# cpsw_ale register map
Vendor: Texas Instruments
Peripheral module from a debugger description file (folder am335x).
Registers are 32-bit, read-write, no defined reset value unless marked. A register's access mark holds for its fields unless they carry their own. Offsets are as the file gives them; lines under a group give offsets from that group; [hi:lo] are bit positions; {n}, {i} and the like mark numbered series; 'fields as' and 'values as' point back to an identical list; <NAME> marks a mode.

## cpsw_ale
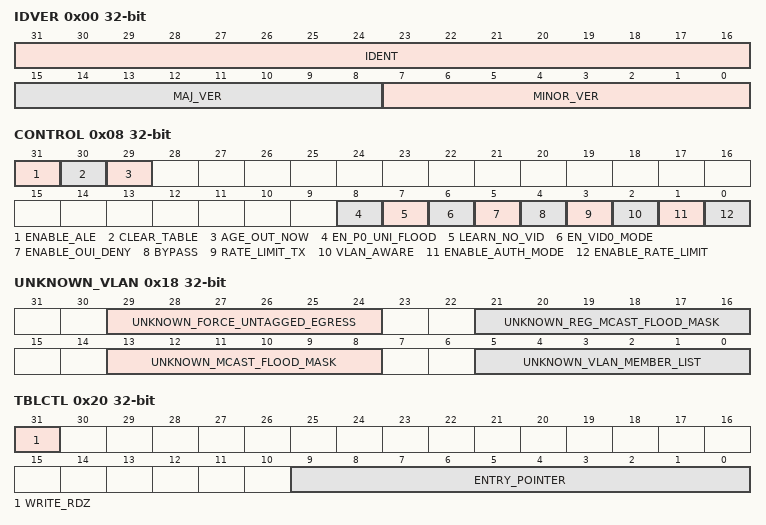
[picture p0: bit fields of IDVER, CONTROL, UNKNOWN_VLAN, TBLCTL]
0x00 IDVER ro — ADDRESS LOOKUP ENGINE ID/VERSION REGISTER
  [31:16] IDENT — ALE Identification Value
  [15:8] MAJ_VER — ALE Major Version Value
  [7:0] MINOR_VER — ALE Minor Version Value
0x08 CONTROL — ADDRESS LOOKUP ENGINE CONTROL REGISTER
  [31] ENABLE_ALE — Enable ALE - 0 - Drop all packets 1 - Enable ALE packet processing
  [30] CLEAR_TABLE — Clear ALE address table - Setting this bit causes the ALE hardware to write all table bit values to zero. Software must perform a clear table operation as part of the ALE setup/configuration process. Setting this bit causes all ALE accesses to be held up for 64 clocks while the clear is performed. Access to all ALE registers will be blocked (wait states) until the 64 clocks have completed. This bit cannot be read as one because the read is blocked until the clear table is completed at which time this bit is cleared to zero.
  [29] AGE_OUT_NOW — Age Out Address Table Now - Setting this bit causes the ALE hardware to remove (free up) any ageable table entry that does not have a set touch bit. This bit is cleared when the age out process has completed. This bit may be read. The age out process takes 4096 clocks best case (no ale packet processing during ageout) and 66550 clocks absolute worst case.
  [8] EN_P0_UNI_FLOOD — Enable Port 0 (Host Port) unicast flood 0 - do not flood unknown unicast packets to host port (p0) 1 - flood unknown unicast packets to host port (p0)
  [7] LEARN_NO_VID — Learn No VID - 0 - VID is learned with the source address 1 - VID is not learned with the source address (source address is not tied to VID).
  [6] EN_VID0_MODE — Enable VLAN ID = 0 Mode 0 - Process the packet with VID = PORT_VLAN[11:0]. 1 - Process the packet with VID = 0.
  [5] ENABLE_OUI_DENY — Enable OUI Deny Mode - When set this bit indicates that a packet with a non OUI table entry matching source address will be dropped to the host unless the destination address matches a multicast table entry with the super bit set.
  [4] BYPASS — ALE Bypass - When set, all packets received on ports 0 and 1 are sent to the host (only to the host).
  [3] RATE_LIMIT_TX — Rate Limit Transmit mode - 0 - Broadcast and multicast rate limit counters are received port based 1 - Broadcast and multicast rate limit counters are transmit port based.
  [2] VLAN_AWARE — ALE VLAN Aware - Determines what is done if VLAN not found. 0 - Flood if VLAN not found 1 - Drop packet if VLAN not found
  [1] ENABLE_AUTH_MODE — Enable MAC Authorization Mode - Mac authorization mode requires that all table entries be made by the host software. There are no learned address in authorization mode and the packet will be dropped if the source address is not found (and the destination address is not a multicast address with the super table entry bit set). 0 - The ALE is not in MAC authorization mode 1 - The ALE is in MAC authorization mode
  [0] ENABLE_RATE_LIMIT — Enable Broadcast and Multicast Rate Limit 0 - Broadcast/Multicast rates not limited 1 - Broadcast/Multicast packet reception limited to the port control register rate limit fields.
0x10 PRESCALE — ADDRESS LOOKUP ENGINE PRESCALE REGISTER
  [19:0] PRESCALE — ALE Prescale Register - The input clock is divided by this value for use in the multicast/broadcast rate limiters. The minimum operating value is 0x10. The prescaler is off when the value is zero.
0x18 UNKNOWN_VLAN — ADDRESS LOOKUP ENGINE UNKNOWN VLAN REGISTER
  [29:24] UNKNOWN_FORCE_UNTAGGED_EGRESS — Unknown VLAN Force Untagged Egress.
  [21:16] UNKNOWN_REG_MCAST_FLOOD_MASK — Unknown VLAN Registered Multicast Flood Mask
  [13:8] UNKNOWN_MCAST_FLOOD_MASK — Unknown VLAN Multicast Flood Mask
  [5:0] UNKNOWN_VLAN_MEMBER_LIST
0x20 TBLCTL — ADDRESS LOOKUP ENGINE TABLE CONTROL
  [31] WRITE_RDZ — Write Bit - This bit is always read as zero. Writing a 1 to this bit causes the three table word register values to be written to the entry_pointer location in the address table. Writing a 0 to this bit causes the three table word register values to be loaded from the entry_pointer location in the address table so that they may be subsequently read. A read of any ALE address location will be stalled until the read or write has completed.
  [9:0] ENTRY_POINTER — Table Entry Pointer - The entry_pointer contains the table entry value that will be read/written with accesses to the table word registers.
0x34 TBLW2 — ADDRESS LOOKUP ENGINE TABLE WORD 2 REGISTER
  [7:0] ENTRY71_64 — Table entry bits 71:64
0x38 TBLW1 — ADDRESS LOOKUP ENGINE TABLE WORD 1 REGISTER
  [31:0] ENTRY63_32 — Table entry bits 63:32
0x3C TBLW0 — ADDRESS LOOKUP ENGINE TABLE WORD 0 REGISTER
  [31:0] ENTRY31_0 — Table entry bits 31:0
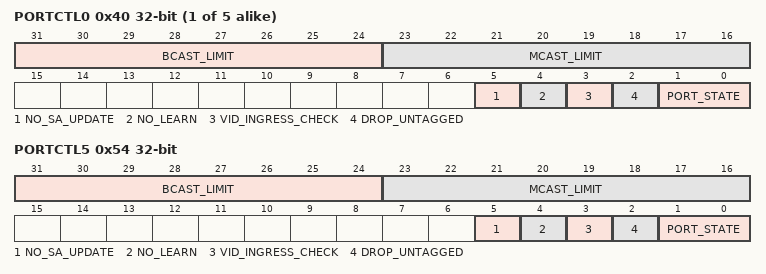
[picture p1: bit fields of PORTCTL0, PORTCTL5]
{0x40+4i} PORTCTL{i} (i=0..4) — ADDRESS LOOKUP ENGINE PORT {i} CONTROL REGISTER
  [31:24] BCAST_LIMIT — Broadcast Packet Rate Limit - Each prescale pulse loads this field into the port broadcast rate limit counter. The port counters are decremented with each packet received or transmitted depending on whether the mode is transmit or receive. If the counters decrement to zero, then further packets are rate limited until the next prescale pulse. Broadcast rate limiting is enabled by a non-zero value in this field
  [23:16] MCAST_LIMIT — Multicast Packet Rate Limit - Each prescale pulse loads this field into the port multicast rate limit counter. The port counters are decremented with each packet received or transmitted depending on whether the mode is transmit or receive. If the counters decrement to zero, then further packets are rate limited until the next prescale pulse. Multicast rate limiting is enabled by a non-zero value in this field.
  [5] NO_SA_UPDATE — No Souce Address Update - When set the port is disabled from updating the source port number in an ALE table entry.
  [4] NO_LEARN — No Learn Mode - When set the port is disabled from learning an address.
  [3] VID_INGRESS_CHECK — VLAN ID Ingress Check - If VLAN not found then drop the packet. Packets with an unknown (default) VLAN will be dropped.
  [2] DROP_UNTAGGED — Drop Untagged Packets - Drop non-VLAN tagged ingress packets.
  [1:0] PORT_STATE — Port State 0 - Disabled 1 - Blocked 2 - Learn 3 - Forward
0x54 PORTCTL5 — ADDRESS LOOKUP ENGINE PORT 5 CONTROL REGISTER
  [31:24] BCAST_LIMIT — Broadcast Packet Rate Limit - Each prescale pulse loads this field into the port broadcast rate limit counter. The port counters are decremented with each packet received or transmitted depending on whether the mode is transmit or receive. If the counters decrement to zero, then further packets are rate limited until the next prescale pulse. Broadcast rate limiting is enabled by a non-zero value in this field
  [23:16] MCAST_LIMIT — Multicast Packet Rate Limit - Each prescale pulse loads this field into the port multicast rate limit counter. The port counters are decremented with each packet received or transmitted depending on whether the mode is transmit or receive. If the counters decrement to zero, then further packets are rate limited until the next prescale pulse. Multicast rate limiting is enabled by a non-zero value in this field.
  [5] NO_SA_UPDATE — No Souce Address Update - When set the port is disabled from updating the source port number in an ALE table entry.
  [4] NO_LEARN — No Learn Mode - When set the port is disabled from learning an address.
  [3] VID_INGRESS_CHECK — VLAN ID Ingress Check - If VLAN not found then drop the packet. Packets with an unknown (default) VLAN will be dropped.
  [2] DROP_UNTAGGED — Drop Untagged Packets - Drop non-VLAN tagged ingress packets.
  [1:0] PORT_STATE — Port State 0 - Disabled 1 - Blocked 2 - Learn
